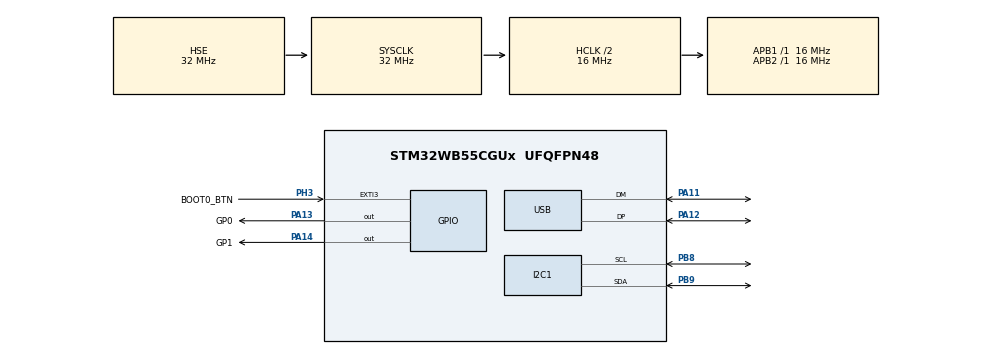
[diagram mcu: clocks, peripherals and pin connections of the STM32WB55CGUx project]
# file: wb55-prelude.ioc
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FREERTOS.Tasks01=defaultTask,24,128,StartDefaultTask,Default,NULL,Dynamic,NULL,NULL
FREERTOS.configOVERRIDE_DEFAULT_TICK_CONFIGURATION=0
FREERTOS.configTOTAL_HEAP_SIZE=32768
FREERTOS.configUSE_TICKLESS_IDLE=1
I2C1.Timing=0x00503D58
Mcu.Family=STM32WB
Mcu.Name=STM32WB55CGUx
Mcu.Package=UFQFPN48
NVIC.EXTI3_IRQn=true\:5\:0\:false\:false\:true\:true\:true\:true\:true
NVIC.HSEM_IRQn=true\:5\:0\:false\:false\:true\:true\:false\:true\:true
NVIC.IPCC_C1_RX_IRQn=true\:5\:0\:false\:false\:true\:true\:true\:true\:true
NVIC.IPCC_C1_TX_IRQn=true\:5\:0\:false\:false\:true\:true\:true\:true\:true
NVIC.PriorityGroup=NVIC_PRIORITYGROUP_4
NVIC.RTC_WKUP_IRQn=true\:5\:0\:false\:false\:true\:true\:true\:true\:true
NVIC.TIM1_TRG_COM_TIM17_IRQn=true\:15\:0\:false\:false\:true\:false\:false\:true\:true
NVIC.TimeBase=TIM1_TRG_COM_TIM17_IRQn
NVIC.TimeBaseIP=TIM17
NVIC.USB_LP_IRQn=true\:5\:0\:false\:false\:true\:true\:false\:true\:true
OSC_IN.Mode=HSE-External-Oscillator
OSC_IN.Signal=RCC_OSC_IN
OSC_OUT.Mode=HSE-External-Oscillator
OSC_OUT.Signal=RCC_OSC_OUT
PA11.Mode=Device
PA11.Signal=USB_DM
PA12.Mode=Device
PA12.Signal=USB_DP
PA13.GPIO_Label=GP0
PA13.Signal=GPIO_Output
PA14.GPIO_Label=GP1
PA14.Signal=GPIO_Output
PB8.Mode=I2C
PB8.Signal=I2C1_SCL
PB9.Mode=I2C
PB9.Signal=I2C1_SDA
PC14-OSC32_IN.Mode=LSE-External-Oscillator
PC14-OSC32_IN.Signal=RCC_OSC32_IN
PC15-OSC32_OUT.Mode=LSE-External-Oscillator
PC15-OSC32_OUT.Signal=RCC_OSC32_OUT
PH3-BOOT0.GPIO_Label=BOOT0_BTN
PH3-BOOT0.GPIO_PuPd=GPIO_PULLDOWN
PH3-BOOT0.Signal=GPXTI3
ProjectManager.HeapSize=0x200
ProjectManager.StackSize=0x400
ProjectManager.TargetToolchain=CMake
RCC.ADCFreq_Value=8000000
RCC.AHBCLKDivider=RCC_SYSCLK_DIV2
RCC.AHBFreq_Value=16000000
RCC.APB1Freq_Value=16000000
RCC.APB1TimFreq_Value=16000000
RCC.APB2Freq_Value=16000000
RCC.APB2TimFreq_Value=16000000
RCC.APB3Freq_Value=16000000
RCC.CK48CLockSelection=RCC_USBCLKSOURCE_HSI48
RCC.CortexFreq_Value=16000000
RCC.HCLKFreq_Value=16000000
RCC.HSE_VALUE=32000000
RCC.HSI48_VALUE=48000000
RCC.HSI_VALUE=16000000
RCC.PLLM=RCC_PLLM_DIV8
RCC.PLLSAI1N=4
RCC.PLLSourceVirtual=RCC_PLLSOURCE_HSE
RCC.RFWKPClockSelection=RCC_RFWKPCLKSOURCE_LSE
RCC.RTCClockSelection=RCC_RTCCLKSOURCE_LSE
RCC.SMPSCLockSelection=RCC_SMPSCLKSOURCE_HSE
RCC.SMPSDivider=4
RCC.SYSCLKFreq_VALUE=32000000
RCC.SYSCLKSource=RCC_SYSCLKSOURCE_HSE
RCC.USBFreq_Value=48000000
RCC.VCOOutputFreq_Value=32000000
RF1.Mode=RF1_Activate
RF1.Signal=RF_RF1
STM32_WPAN.AD_TYPE_COMPLETE_LOCAL_NAME=WB55-Prelude
STM32_WPAN.AD_TYPE_COMPLETE_LOCAL_NAME_LENGTH=13
STM32_WPAN.BT_SIG_HEART_RATE_SENSOR=Disabled
STM32_WPAN.CFG_DEBUGGER_SUPPORTED=0
STM32_WPAN.CFG_GAP_DEVICE_NAME=WB55-Prelude
STM32_WPAN.CFG_LPM_SUPPORTED=1
STM32_WPAN.CFG_LSCLK_LSE=0
STM32_WPAN.CFG_TX_POWER=(0x19) /* 0dBm */
STM32_WPAN.INCLUDE_AD_TYPE_COMPLETE_LOCAL_NAME=1
STM32_WPAN.NUMBER_OF_SERVICES=1
STM32_WPAN.SERVICE1_CHAR1_GATT_NOTIFY_READ_REQ_AND_WAIT_FOR_APPL_RESP=\ 
STM32_WPAN.SERVICE1_CHAR1_GATT_NOTIFY_WRITE_REQ_AND_WAIT_FOR_APPL_RESP=\ 
STM32_WPAN.SERVICE1_CHAR1_LONG_NAME=LEDWrite
STM32_WPAN.SERVICE1_CHAR1_PROP_WRITE=CHAR_PROP_WRITE
STM32_WPAN.SERVICE1_CHAR1_SHORT_NAME=LEDWrite
STM32_WPAN.SERVICE1_LONG_NAME=LED_Control
STM32_WPAN.SERVICE1_SHORT_NAME=LED
USB_DEVICE.CLASS_NAME_FS=CDC
USB_DEVICE.VirtualMode=Cdc
USB_DEVICE.VirtualModeFS=Cdc_FS
VP_FREERTOS_VS_CMSIS_V2.Mode=CMSIS_V2
VP_HSEM_VS_HSEM.Mode=HSEM_Activate
VP_IPCC_VS_IPCC.Mode=IPCC_Activate
VP_MEMORYMAP_VS_MEMORYMAP.Mode=CurAppReg
VP_RCC_LSE.Mode=CRS SYNC Source LSE
VP_RTC_VS_RTC_Activate.Mode=RTC_Enabled
VP_RTC_VS_RTC_WakeUp_intern.Mode=WakeUp
VP_STM32_WPAN_VS_BLE_HOST.Mode=STM32_WPAN_Enabled
VP_SYS_VS_tim17.Mode=TIM17
VP_TINY_LPM_VS_TINY_LPM.Mode=TINY_LPM_Enabled
VP_USB_DEVICE_VS_USB_DEVICE_CDC_FS.Mode=CDC_FS
board=custom

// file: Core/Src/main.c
/* USER CODE BEGIN Header */
/**
  ******************************************************************************
  * @file           : main.c
  * @brief          : Main program body
  ******************************************************************************
  * @attention
  *
  * Copyright (c) 2026 STMicroelectronics.
  * All rights reserved.
  *
  * This software is licensed under terms that can be found in the LICENSE file
  * in the root directory of this software component.
  * If no LICENSE file comes with this software, it is provided AS-IS.
  *
  ******************************************************************************
  */
/* USER CODE END Header */
#include "main.h"
#include "cmsis_os2.h"
#include "FreeRTOS.h"
#include "usb_device.h"

/* USER CODE BEGIN Includes */
#include "app_sensors.h"
#include "stm32_lpm.h"

/* USER CODE END Includes */

I2C_HandleTypeDef hi2c1;

IPCC_HandleTypeDef hipcc;

RTC_HandleTypeDef hrtc;

/* Definitions for defaultTask */
osThreadId_t defaultTaskHandle;
const osThreadAttr_t defaultTask_attributes = {
  .name = "defaultTask",
  .priority = (osPriority_t) osPriorityNormal,
  .stack_size = 128 * 4
};

void SystemClock_Config(void);
void PeriphCommonClock_Config(void);
static void MX_GPIO_Init(void);
static void MX_I2C1_Init(void);
static void MX_IPCC_Init(void);
static void MX_RTC_Init(void);
static void MX_RF_Init(void);
void StartDefaultTask(void *argument);

int main(void)
{

  /* MCU Configuration--------------------------------------------------------*/

  /* Reset of all peripherals, Initializes the Flash interface and the Systick. */
  HAL_Init();
  /* Config code for STM32_WPAN (HSE Tuning must be done before system clock configuration) */
  MX_APPE_Config();

  /* Configure the system clock */
  SystemClock_Config();

  /* Configure the peripherals common clocks */
  PeriphCommonClock_Config();

  /* IPCC initialisation */
  MX_IPCC_Init();

  /* Initialize all configured peripherals */
  MX_GPIO_Init();
  MX_I2C1_Init();
  MX_RTC_Init();
  MX_RF_Init();
  /* USER CODE BEGIN 2 */
  //LL_LPM_EnableSleep();

  /* USER CODE END 2 */

  /* Init scheduler */
  osKernelInitialize();

  /* Create the thread(s) */
  /* creation of defaultTask */
  defaultTaskHandle = osThreadNew(StartDefaultTask, NULL, &defaultTask_attributes);

  /* Init code for STM32_WPAN */
  MX_APPE_Init();

  /* Start scheduler */
  osKernelStart();

  /* We should never get here as control is now taken by the scheduler */

  /* Infinite loop */
  while (1)
  {

  }
}

void SystemClock_Config(void)
{
  RCC_OscInitTypeDef RCC_OscInitStruct = {0};
  RCC_ClkInitTypeDef RCC_ClkInitStruct = {0};
  RCC_CRSInitTypeDef RCC_CRSInitStruct = {0};

  /** Configure LSE Drive Capability
  */
  HAL_PWR_EnableBkUpAccess();
  __HAL_RCC_LSEDRIVE_CONFIG(RCC_LSEDRIVE_MEDIUMHIGH);

  /** Configure the main internal regulator output voltage
  */
  __HAL_PWR_VOLTAGESCALING_CONFIG(PWR_REGULATOR_VOLTAGE_SCALE1);

  /** Initializes the RCC Oscillators according to the specified parameters
  * in the RCC_OscInitTypeDef structure.
  */
  RCC_OscInitStruct.OscillatorType = RCC_OSCILLATORTYPE_HSI48|RCC_OSCILLATORTYPE_HSI
                              |RCC_OSCILLATORTYPE_HSE|RCC_OSCILLATORTYPE_LSE;
  RCC_OscInitStruct.HSEState = RCC_HSE_ON;
  RCC_OscInitStruct.LSEState = RCC_LSE_ON;
  RCC_OscInitStruct.HSIState = RCC_HSI_ON;
  RCC_OscInitStruct.HSI48State = RCC_HSI48_ON;
  RCC_OscInitStruct.HSICalibrationValue = RCC_HSICALIBRATION_DEFAULT;
  RCC_OscInitStruct.PLL.PLLState = RCC_PLL_NONE;
  if (HAL_RCC_OscConfig(&RCC_OscInitStruct) != HAL_OK)
  {
    Error_Handler();
  }

  /** Configure the SYSCLKSource, HCLK, PCLK1 and PCLK2 clocks dividers
  */
  RCC_ClkInitStruct.ClockType = RCC_CLOCKTYPE_HCLK4|RCC_CLOCKTYPE_HCLK2
                              |RCC_CLOCKTYPE_HCLK|RCC_CLOCKTYPE_SYSCLK
                              |RCC_CLOCKTYPE_PCLK1|RCC_CLOCKTYPE_PCLK2;
  RCC_ClkInitStruct.SYSCLKSource = RCC_SYSCLKSOURCE_HSE;
  RCC_ClkInitStruct.AHBCLKDivider = RCC_SYSCLK_DIV2;
  RCC_ClkInitStruct.APB1CLKDivider = RCC_HCLK_DIV1;
  RCC_ClkInitStruct.APB2CLKDivider = RCC_HCLK_DIV1;
  RCC_ClkInitStruct.AHBCLK2Divider = RCC_SYSCLK_DIV1;
  RCC_ClkInitStruct.AHBCLK4Divider = RCC_SYSCLK_DIV1;

  if (HAL_RCC_ClockConfig(&RCC_ClkInitStruct, FLASH_LATENCY_1) != HAL_OK)
  {
    Error_Handler();
  }

  /** Enable the SYSCFG APB clock
  */
  __HAL_RCC_CRS_CLK_ENABLE();

  /** Configures CRS
  */
  RCC_CRSInitStruct.Prescaler = RCC_CRS_SYNC_DIV1;
  RCC_CRSInitStruct.Source = RCC_CRS_SYNC_SOURCE_LSE;
  RCC_CRSInitStruct.Polarity = RCC_CRS_SYNC_POLARITY_RISING;
  RCC_CRSInitStruct.ReloadValue = __HAL_RCC_CRS_RELOADVALUE_CALCULATE(48000000,32768);
  RCC_CRSInitStruct.ErrorLimitValue = 34;
  RCC_CRSInitStruct.HSI48CalibrationValue = 32;

  HAL_RCCEx_CRSConfig(&RCC_CRSInitStruct);
}

void PeriphCommonClock_Config(void)
{
  RCC_PeriphCLKInitTypeDef PeriphClkInitStruct = {0};

  /** Initializes the peripherals clock
  */
  PeriphClkInitStruct.PeriphClockSelection = RCC_PERIPHCLK_SMPS|RCC_PERIPHCLK_RFWAKEUP;
  PeriphClkInitStruct.RFWakeUpClockSelection = RCC_RFWKPCLKSOURCE_LSE;
  PeriphClkInitStruct.SmpsClockSelection = RCC_SMPSCLKSOURCE_HSE;
  PeriphClkInitStruct.SmpsDivSelection = RCC_SMPSCLKDIV_RANGE1;

  if (HAL_RCCEx_PeriphCLKConfig(&PeriphClkInitStruct) != HAL_OK)
  {
    Error_Handler();
  }
}

static void MX_I2C1_Init(void)
{

  hi2c1.Instance = I2C1;
  hi2c1.Init.Timing = 0x00503D58;
  hi2c1.Init.OwnAddress1 = 0;
  hi2c1.Init.AddressingMode = I2C_ADDRESSINGMODE_7BIT;
  hi2c1.Init.DualAddressMode = I2C_DUALADDRESS_DISABLE;
  hi2c1.Init.OwnAddress2 = 0;
  hi2c1.Init.OwnAddress2Masks = I2C_OA2_NOMASK;
  hi2c1.Init.GeneralCallMode = I2C_GENERALCALL_DISABLE;
  hi2c1.Init.NoStretchMode = I2C_NOSTRETCH_DISABLE;
  if (HAL_I2C_Init(&hi2c1) != HAL_OK)
  {
    Error_Handler();
  }

  /** Configure Analogue filter
  */
  if (HAL_I2CEx_ConfigAnalogFilter(&hi2c1, I2C_ANALOGFILTER_ENABLE) != HAL_OK)
  {
    Error_Handler();
  }

  /** Configure Digital filter
  */
  if (HAL_I2CEx_ConfigDigitalFilter(&hi2c1, 0) != HAL_OK)
  {
    Error_Handler();
  }

}

static void MX_IPCC_Init(void)
{

  hipcc.Instance = IPCC;
  if (HAL_IPCC_Init(&hipcc) != HAL_OK)
  {
    Error_Handler();
  }

}

static void MX_RF_Init(void)
{

}

static void MX_RTC_Init(void)
{

  /** Initialize RTC Only
  */
  hrtc.Instance = RTC;
  hrtc.Init.HourFormat = RTC_HOURFORMAT_24;
  hrtc.Init.AsynchPrediv = CFG_RTC_ASYNCH_PRESCALER;
  hrtc.Init.SynchPrediv = CFG_RTC_SYNCH_PRESCALER;
  hrtc.Init.OutPut = RTC_OUTPUT_DISABLE;
  hrtc.Init.OutPutPolarity = RTC_OUTPUT_POLARITY_HIGH;
  hrtc.Init.OutPutType = RTC_OUTPUT_TYPE_OPENDRAIN;
  hrtc.Init.OutPutRemap = RTC_OUTPUT_REMAP_NONE;
  if (HAL_RTC_Init(&hrtc) != HAL_OK)
  {
    Error_Handler();
  }

  /** Enable the WakeUp
  */
  if (HAL_RTCEx_SetWakeUpTimer_IT(&hrtc, 0, RTC_WAKEUPCLOCK_RTCCLK_DIV16) != HAL_OK)
  {
    Error_Handler();
  }

}

static void MX_GPIO_Init(void)
{
  GPIO_InitTypeDef GPIO_InitStruct = {0};

  /* GPIO Ports Clock Enable */
  __HAL_RCC_GPIOC_CLK_ENABLE();
  __HAL_RCC_GPIOH_CLK_ENABLE();
  __HAL_RCC_GPIOB_CLK_ENABLE();
  __HAL_RCC_GPIOA_CLK_ENABLE();

  /*Configure GPIO pin Output Level */
  HAL_GPIO_WritePin(GPIOA, GP0_Pin|GP1_Pin, GPIO_PIN_RESET);

  /*Configure GPIO pin : BOOT0_BTN_Pin */
  GPIO_InitStruct.Pin = BOOT0_BTN_Pin;
  GPIO_InitStruct.Mode = GPIO_MODE_IT_RISING;
  GPIO_InitStruct.Pull = GPIO_PULLDOWN;
  HAL_GPIO_Init(BOOT0_BTN_GPIO_Port, &GPIO_InitStruct);

  /*Configure GPIO pins : GP0_Pin GP1_Pin */
  GPIO_InitStruct.Pin = GP0_Pin|GP1_Pin;
  GPIO_InitStruct.Mode = GPIO_MODE_OUTPUT_PP;
  GPIO_InitStruct.Pull = GPIO_NOPULL;
  GPIO_InitStruct.Speed = GPIO_SPEED_FREQ_LOW;
  HAL_GPIO_Init(GPIOA, &GPIO_InitStruct);

  /* EXTI interrupt init*/
  HAL_NVIC_SetPriority(EXTI3_IRQn, 5, 0);
  HAL_NVIC_EnableIRQ(EXTI3_IRQn);

}

void StartDefaultTask(void *argument)
{
  /* init code for USB_Device */
  MX_USB_Device_Init();
  /* USER CODE BEGIN 5 */
  Sensors_Init();
  /* Infinite loop */
  for(;;)
  {
    Sensors_Task();
    osDelay(100);
  }
  /* USER CODE END 5 */
}

void HAL_TIM_PeriodElapsedCallback(TIM_HandleTypeDef *htim)
{
  if (htim->Instance == TIM17)
  {
    HAL_IncTick();
  }
}

void Error_Handler(void)
{
  __disable_irq();
  while (1)
  {
  }
}
